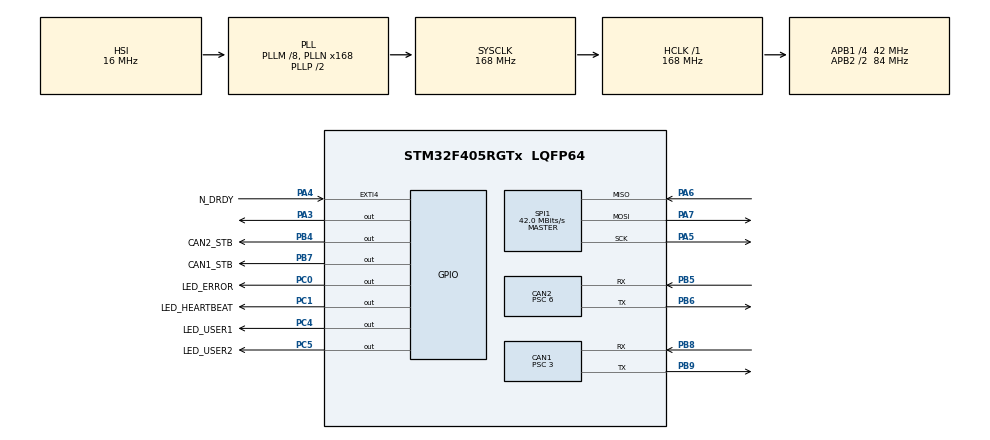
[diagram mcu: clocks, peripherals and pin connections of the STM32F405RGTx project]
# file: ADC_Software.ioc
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CAN1.BS1=CAN_BS1_11TQ
CAN1.BS2=CAN_BS2_2TQ
CAN1.CalculateBaudRate=1000000
CAN1.CalculateTimeBit=1000
CAN1.CalculateTimeQuantum=71.42857142857143
CAN1.Prescaler=3
CAN2.BS1=CAN_BS1_11TQ
CAN2.BS2=CAN_BS2_2TQ
CAN2.CalculateBaudRate=500000
CAN2.CalculateTimeBit=2000
CAN2.CalculateTimeQuantum=142.85714285714286
CAN2.Prescaler=6
Mcu.Family=STM32F4
Mcu.Name=STM32F405RGTx
Mcu.Package=LQFP64
NVIC.CAN1_RX0_IRQn=true\:0\:0\:false\:false\:true\:true\:true\:true
NVIC.EXTI4_IRQn=true\:0\:0\:false\:false\:true\:true\:true\:true
NVIC.PriorityGroup=NVIC_PRIORITYGROUP_4
NVIC.SPI1_IRQn=true\:0\:0\:false\:false\:true\:true\:true\:true
NVIC.TIM7_IRQn=true\:0\:0\:false\:false\:true\:true\:true\:true
PA13.Mode=Trace_Asynchronous_SW
PA13.Signal=SYS_JTMS-SWDIO
PA14.Mode=Trace_Asynchronous_SW
PA14.Signal=SYS_JTCK-SWCLK
PA3.Signal=GPIO_Output
PA4.GPIO_Label=N_DRDY
PA4.GPIO_ModeDefaultEXTI=GPIO_MODE_IT_FALLING
PA4.GPIO_PuPd=GPIO_PULLUP
PA4.Signal=GPXTI4
PA5.Mode=Full_Duplex_Master
PA5.Signal=SPI1_SCK
PA6.Mode=Full_Duplex_Master
PA6.Signal=SPI1_MISO
PA7.Mode=Full_Duplex_Master
PA7.Signal=SPI1_MOSI
PB3.Mode=Trace_Asynchronous_SW
PB3.Signal=SYS_JTDO-SWO
PB4.GPIO_Label=CAN2_STB
PB4.Signal=GPIO_Output
PB5.Mode=CAN_Activate
PB5.Signal=CAN2_RX
PB6.Mode=CAN_Activate
PB6.Signal=CAN2_TX
PB7.GPIO_Label=CAN1_STB
PB7.Signal=GPIO_Output
PB8.Mode=CAN_Activate
PB8.Signal=CAN1_RX
PB9.Mode=CAN_Activate
PB9.Signal=CAN1_TX
PC0.GPIO_Label=LED_ERROR
PC0.Signal=GPIO_Output
PC1.GPIO_Label=LED_HEARTBEAT
PC1.Signal=GPIO_Output
PC4.GPIO_Label=LED_USER1
PC4.Signal=GPIO_Output
PC5.GPIO_Label=LED_USER2
PC5.Signal=GPIO_Output
PH0-OSC_IN.Mode=HSE-External-Oscillator
PH0-OSC_IN.Signal=RCC_OSC_IN
PH1-OSC_OUT.Mode=HSE-External-Oscillator
PH1-OSC_OUT.Signal=RCC_OSC_OUT
ProjectManager.HeapSize=0x200
ProjectManager.StackSize=0x400
ProjectManager.TargetToolchain=MDK-ARM V5.32
RCC.48MHZClocksFreq_Value=84000000
RCC.AHBFreq_Value=168000000
RCC.APB1CLKDivider=RCC_HCLK_DIV4
RCC.APB1Freq_Value=42000000
RCC.APB1TimFreq_Value=84000000
RCC.APB2CLKDivider=RCC_HCLK_DIV2
RCC.APB2Freq_Value=84000000
RCC.APB2TimFreq_Value=168000000
RCC.CortexFreq_Value=168000000
RCC.HCLKFreq_Value=168000000
RCC.HSE_VALUE=12000000
RCC.HSI_VALUE=16000000
RCC.LSE_VALUE=32768
RCC.PLLM=8
RCC.PLLN=168
RCC.SYSCLKFreq_VALUE=168000000
RCC.SYSCLKSource=RCC_SYSCLKSOURCE_PLLCLK
RCC.VCOOutputFreq_Value=336000000
SPI1.CalculateBaudRate=42.0 MBits/s
SPI1.Direction=SPI_DIRECTION_2LINES
SPI1.Mode=SPI_MODE_MASTER
SPI1.VirtualType=VM_MASTER
TIM2.AutoReloadPreload=TIM_AUTORELOAD_PRELOAD_ENABLE
TIM2.Period=10000
TIM2.Prescaler=84
TIM3.AutoReloadPreload=TIM_AUTORELOAD_PRELOAD_ENABLE
TIM3.Period=500
TIM3.Prescaler=84
TIM5.AutoReloadPreload=TIM_AUTORELOAD_PRELOAD_ENABLE
TIM5.Period=10000
TIM5.Prescaler=84
TIM7.AutoReloadPreload=TIM_AUTORELOAD_PRELOAD_DISABLE
TIM7.Period=5000
TIM7.Prescaler=8399
TIM8.AutoReloadPreload=TIM_AUTORELOAD_PRELOAD_ENABLE
TIM8.Period=500
TIM8.Prescaler=168
VP_TIM2_VS_ClockSourceINT.Mode=Internal
VP_TIM3_VS_ClockSourceINT.Mode=Internal
VP_TIM5_VS_ClockSourceINT.Mode=Internal
VP_TIM7_VS_ClockSourceINT.Mode=Enable_Timer
VP_TIM8_VS_ClockSourceINT.Mode=Internal
board=custom

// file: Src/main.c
/* USER CODE BEGIN Header */
/**
  ******************************************************************************
  * @file           : main.c
  * @brief          : Main program body
  ******************************************************************************
  * @attention
  *
  * Copyright (c) 2024 STMicroelectronics.
  * All rights reserved.
  *
  * This software is licensed under terms that can be found in the LICENSE file
  * in the root directory of this software component.
  * If no LICENSE file comes with this software, it is provided AS-IS.
  *
  ******************************************************************************
  */
/* USER CODE END Header */
#include "main.h"
#include "can.h"
#include "spi.h"
#include "tim.h"
#include "gpio.h"
#include "hal.h"

/* USER CODE BEGINIncludes */
#include "ads131m0x.h"
#include "sub_functions.h"
/* USER CODE END Includes */

/* USER CODE BEGIN PV */
uint8_t ADC_Platine_F = 1;
uint8_t TxData_ADC[8];
bool ITM_debug = 1;

/* USER CODE END PV */

void SystemClock_Config(void);

int main(void)
{

  /* MCU Configuration--------------------------------------------------------*/

  /* Reset of all peripherals, Initializes the Flash interface and the Systick. */
  HAL_Init();

  /* Configure the system clock */
  SystemClock_Config();

  /* Initialize all configured peripherals */
  MX_GPIO_Init();
  MX_CAN1_Init();
  MX_CAN2_Init();
  MX_TIM2_Init();
  MX_TIM3_Init();
  MX_TIM5_Init();
  MX_TIM8_Init();
  MX_SPI1_Init();
  MX_TIM7_Init();

	/* USER CODE BEGIN 2 */
	//HAL_TIM_Base_Start_IT(&htim7); //nacschauen ob Sinn hat

	HAL_Delay(500);

	can_init(); 									// Can initialisieren
	HAL_Delay(500);

	adcStartup();

	//Reset pin vom adc, adc neu starten
	//HAL_GPIO_WritePin(GPIOA, nSYNC_nRESET_PIN, true);

	//HAL_GPIO_WritePin(LED_HEARTBEAT_GPIO_Port, LED_HEARTBEAT_Pin, GPIO_PIN_SET);
  /* USER CODE END 2 */

  /* Infinite loop */
  /* USER CODE BEGIN WHILE */
	ITM_SendString("Test");
	adc_channel_data ADC_Daten;

//  ADC_Daten.response = 0;
//	ADC_Daten.crc = 0;
//	ADC_Daten.channel0 = 0;
//	ADC_Daten.channel1 = 0;
//	ADC_Daten.channel2 = 0;
//	ADC_Daten.channel3 = 0;

  while (1)
  {
    /* USER CODE END WHILE */
			readData(&ADC_Daten);
		  type_conversion01(&ADC_Daten, TxData_ADC);
			can_send_ADC(TxData_ADC);
			delay_ms(500);
  }
}

//ABLAUF:
//auf data rdy warten
//readdata
//can_send

void SystemClock_Config(void)
{
  RCC_OscInitTypeDef RCC_OscInitStruct = {0};
  RCC_ClkInitTypeDef RCC_ClkInitStruct = {0};

  /** Configure the main internal regulator output voltage
  */
  __HAL_RCC_PWR_CLK_ENABLE();
  __HAL_PWR_VOLTAGESCALING_CONFIG(PWR_REGULATOR_VOLTAGE_SCALE1);

  /** Initializes the RCC Oscillators according to the specified parameters
  * in the RCC_OscInitTypeDef structure.
  */
  RCC_OscInitStruct.OscillatorType = RCC_OSCILLATORTYPE_HSI;
  RCC_OscInitStruct.HSIState = RCC_HSI_ON;
  RCC_OscInitStruct.HSICalibrationValue = RCC_HSICALIBRATION_DEFAULT;
  RCC_OscInitStruct.PLL.PLLState = RCC_PLL_ON;
  RCC_OscInitStruct.PLL.PLLSource = RCC_PLLSOURCE_HSI;
  RCC_OscInitStruct.PLL.PLLM = 8;
  RCC_OscInitStruct.PLL.PLLN = 168;
  RCC_OscInitStruct.PLL.PLLP = RCC_PLLP_DIV2;
  RCC_OscInitStruct.PLL.PLLQ = 4;
  if (HAL_RCC_OscConfig(&RCC_OscInitStruct) != HAL_OK)
  {
    Error_Handler();
  }

  /** Initializes the CPU, AHB and APB buses clocks
  */
  RCC_ClkInitStruct.ClockType = RCC_CLOCKTYPE_HCLK|RCC_CLOCKTYPE_SYSCLK
                              |RCC_CLOCKTYPE_PCLK1|RCC_CLOCKTYPE_PCLK2;
  RCC_ClkInitStruct.SYSCLKSource = RCC_SYSCLKSOURCE_PLLCLK;
  RCC_ClkInitStruct.AHBCLKDivider = RCC_SYSCLK_DIV1;
  RCC_ClkInitStruct.APB1CLKDivider = RCC_HCLK_DIV4;
  RCC_ClkInitStruct.APB2CLKDivider = RCC_HCLK_DIV2;

  if (HAL_RCC_ClockConfig(&RCC_ClkInitStruct, FLASH_LATENCY_5) != HAL_OK)
  {
    Error_Handler();
  }
}

void Error_Handler(void)
{
  __disable_irq();
  while (1)
  {
  }
}
